# PIC32MX130F064B device description
Architecture: MIPS; Family: PIC32MX; Series: PIC32MX
Registers are 32-bit, read-write, no defined reset value unless marked. A register's access mark holds for its fields unless they carry their own. Offsets are from the block's base; [hi:lo] are bit positions; 'fields as' and 'values as' point back to an identical list.

## NVM
Instances: NVM 0x1f80f400 in periph1
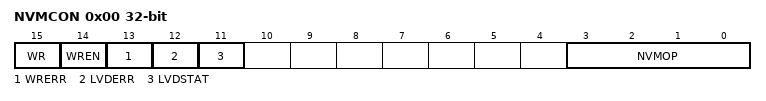
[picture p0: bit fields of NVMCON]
0x00 NVMCON — Programming Control Register
  [15] WR — Write Control bit
    1=Initiate a Flash operation. Hardware clears this bit when the operation completes; 0=Flash operation complete or inactive
  [14] WREN — Write Enable bit
    1=Enable writes to WR bit and enables LVD circuit; 0=Disable writes to WR bit and disables LVD circuit
  [13] WRERR — Write Error bit
    1=Program or erase sequence did not complete successfully; 0=Program or erase sequence completed normally
  [12] LVDERR — Low-Voltage Detect Error bit (LVD circuit must be enabled)
    1=Low-voltage detected (possible data corruption if WRERR is set); 0=Voltage level is acceptable for programming
  [11] LVDSTAT — Low-Voltage Detect Status bit (LVD circuit must be enabled)
    1=Low-voltage event active; 0=Low-voltage event NOT active
  [3:0] NVMOP — NVM Operation bits
    6=No operation; 5=Program Flash (PFM) erase operation: erases PFM if all pages are not write-protected; 4=Page erase operation: erases page selected by NVMADDR if it is not write-protected; 3=Row program operation: programs row selected by NVMADDR if it is not write-protected; 2=No operation; 1=Word program operation: programs word selected by NVMADDR if it is not write-protected; 0=No operation
0x10 NVMKEY wo — Programming Unlock Register
0x20 NVMADDR — Flash Address Register
0x30 NVMDATA
0x40 NVMSRCADDR — Source Data Address Register

## OCMP
Instances: OCMP 0x1f803000 in periph0
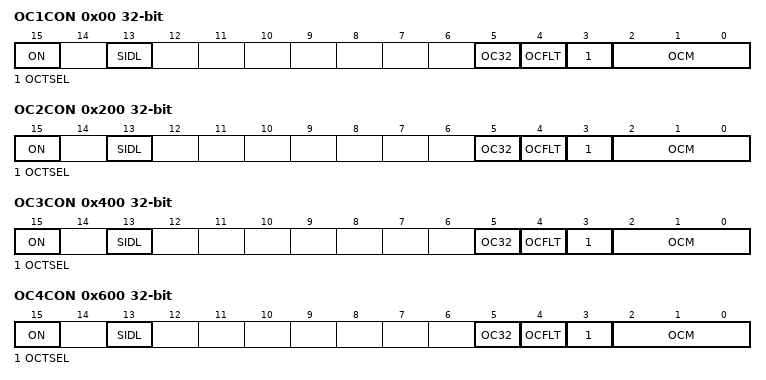
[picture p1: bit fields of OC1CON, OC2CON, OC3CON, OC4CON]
0x00 OC1CON — Output Compare 'x' Control Register
  [15] ON — Output Compare Peripheral On bit
    1=Output Compare peripheral is enabled; 0=Output Compare peripheral is disabled
  [13] SIDL — Stop in Idle Mode bit
    1=Discontinue operation when CPU enters Idle mode; 0=Continue operation in Idle mode
  [5] OC32 — 32-bit Compare Mode bit
    1=OCxR(31-0) and/or OCxRS(31-0) are used for comparisions to the 32-bit timer source; 0=OCxR(15-0) and OCxRS(15-0) are used for comparisons to the 16-bit timer source
  [4] OCFLT — PWM Fault Condition Status bit
    1=PWM Fault condition has occurred (cleared in HW only); 0=No PWM Fault condition has occurred
  [3] OCTSEL — Output Compare Timer Select bit
    1=Timer3 is the clock source for this Output Compare module; 0=Timer2 is the clock source for this Output Compare module
  [2:0] OCM — Output Compare Mode Select bits
    7=PWM mode on OCx; Fault pin enabled; 6=PWM mode on OCx; Fault pin disabled; 5=Initialize OCx pin low; generate continious output pulses on OCx pin; 4=Initialize OCx pin low: generate single output pulse on OCx pin; 3=Compare event toggles OCx pin; 2=Initialize OCx pin high; compare event forces OCx pin low; 1=Initialize OCx pin low; compare event forces OCx pin high; 0=Output compare peripheral is disabled but continues to draw current
0x10 OC1R
0x20 OC1RS
0x200 OC2CON — Output Compare 'x' Control Register
  fields as OC1CON
0x210 OC2R
0x220 OC2RS
0x400 OC3CON — Output Compare 'x' Control Register
  fields as OC1CON
0x410 OC3R
0x420 OC3RS
0x600 OC4CON — Output Compare 'x' Control Register
  fields as OC1CON
0x610 OC4R
0x620 OC4RS
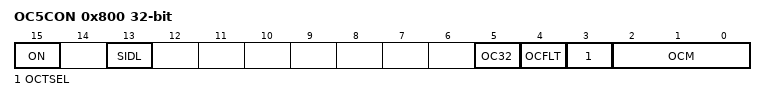
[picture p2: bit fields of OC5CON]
0x800 OC5CON — Output Compare 'x' Control Register
  fields as OC1CON
0x810 OC5R
0x820 OC5RS

## PORT
Instances: PORT 0x1f886000 in periph2
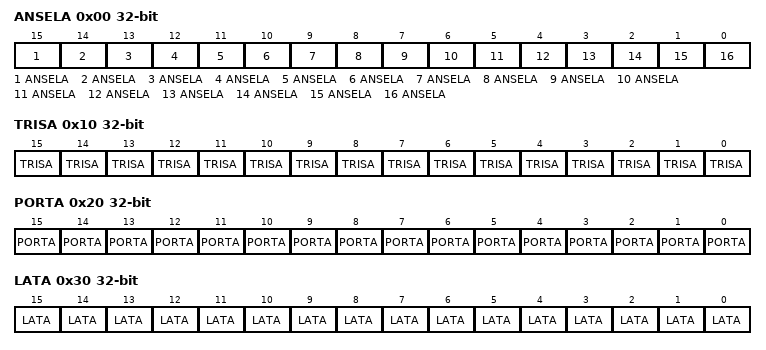
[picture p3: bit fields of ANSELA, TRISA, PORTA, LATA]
0x00 ANSELA
  [15] ANSELA, [14] ANSELA, [13] ANSELA, [12] ANSELA, [11] ANSELA, [10] ANSELA, [9] ANSELA, [8] ANSELA, [7] ANSELA, [6] ANSELA, [5] ANSELA, [4] ANSELA, [3] ANSELA, [2] ANSELA, [1] ANSELA, [0] ANSELA
0x10 TRISA
  [15] TRISA, [14] TRISA, [13] TRISA, [12] TRISA, [11] TRISA, [10] TRISA, [9] TRISA, [8] TRISA, [7] TRISA, [6] TRISA, [5] TRISA, [4] TRISA, [3] TRISA, [2] TRISA, [1] TRISA, [0] TRISA
0x20 PORTA
  [15] PORTA, [14] PORTA, [13] PORTA, [12] PORTA, [11] PORTA, [10] PORTA, [9] PORTA, [8] PORTA, [7] PORTA, [6] PORTA, [5] PORTA, [4] PORTA, [3] PORTA, [2] PORTA, [1] PORTA, [0] PORTA
0x30 LATA
  [15] LATA, [14] LATA, [13] LATA, [12] LATA, [11] LATA, [10] LATA, [9] LATA, [8] LATA, [7] LATA, [6] LATA, [5] LATA, [4] LATA, [3] LATA, [2] LATA, [1] LATA, [0] LATA
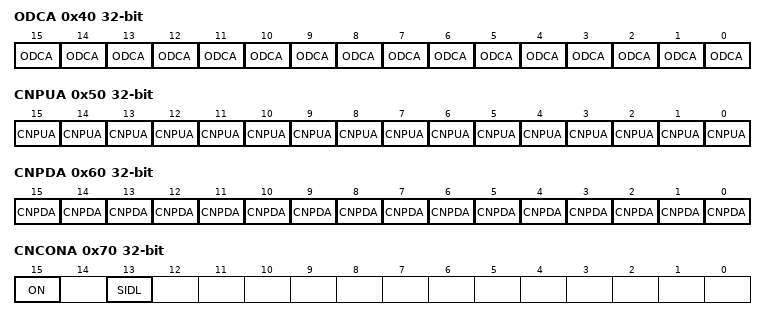
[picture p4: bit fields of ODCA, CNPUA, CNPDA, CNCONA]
0x40 ODCA
  [15] ODCA, [14] ODCA, [13] ODCA, [12] ODCA, [11] ODCA, [10] ODCA, [9] ODCA, [8] ODCA, [7] ODCA, [6] ODCA, [5] ODCA, [4] ODCA, [3] ODCA, [2] ODCA, [1] ODCA, [0] ODCA
0x50 CNPUA
  [15] CNPUA, [14] CNPUA, [13] CNPUA, [12] CNPUA, [11] CNPUA, [10] CNPUA, [9] CNPUA, [8] CNPUA, [7] CNPUA, [6] CNPUA, [5] CNPUA, [4] CNPUA, [3] CNPUA, [2] CNPUA, [1] CNPUA, [0] CNPUA
0x60 CNPDA
  [15] CNPDA, [14] CNPDA, [13] CNPDA, [12] CNPDA, [11] CNPDA, [10] CNPDA, [9] CNPDA, [8] CNPDA, [7] CNPDA, [6] CNPDA, [5] CNPDA, [4] CNPDA, [3] CNPDA, [2] CNPDA, [1] CNPDA, [0] CNPDA
0x70 CNCONA
  [15] ON, [13] SIDL
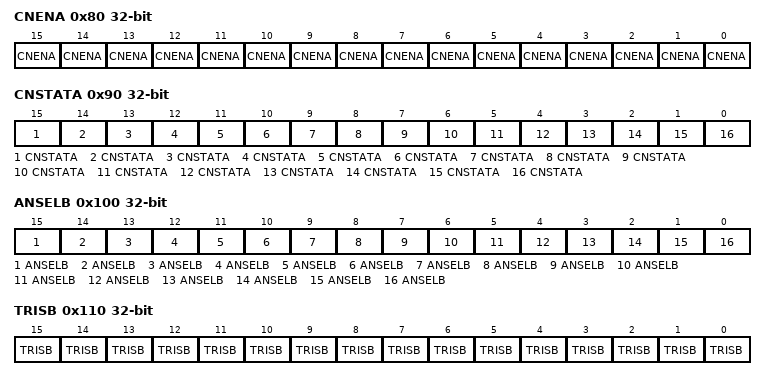
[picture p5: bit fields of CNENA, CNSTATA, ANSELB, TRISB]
0x80 CNENA
  [15] CNENA, [14] CNENA, [13] CNENA, [12] CNENA, [11] CNENA, [10] CNENA, [9] CNENA, [8] CNENA, [7] CNENA, [6] CNENA, [5] CNENA, [4] CNENA, [3] CNENA, [2] CNENA, [1] CNENA, [0] CNENA
0x90 CNSTATA
  [15] CNSTATA, [14] CNSTATA, [13] CNSTATA, [12] CNSTATA, [11] CNSTATA, [10] CNSTATA, [9] CNSTATA, [8] CNSTATA, [7] CNSTATA, [6] CNSTATA, [5] CNSTATA, [4] CNSTATA, [3] CNSTATA, [2] CNSTATA, [1] CNSTATA, [0] CNSTATA
0x100 ANSELB
  [15] ANSELB, [14] ANSELB, [13] ANSELB, [12] ANSELB, [11] ANSELB, [10] ANSELB, [9] ANSELB, [8] ANSELB, [7] ANSELB, [6] ANSELB, [5] ANSELB, [4] ANSELB, [3] ANSELB, [2] ANSELB, [1] ANSELB, [0] ANSELB
0x110 TRISB
  [15] TRISB, [14] TRISB, [13] TRISB, [12] TRISB, [11] TRISB, [10] TRISB, [9] TRISB, [8] TRISB, [7] TRISB, [6] TRISB, [5] TRISB, [4] TRISB, [3] TRISB, [2] TRISB, [1] TRISB, [0] TRISB
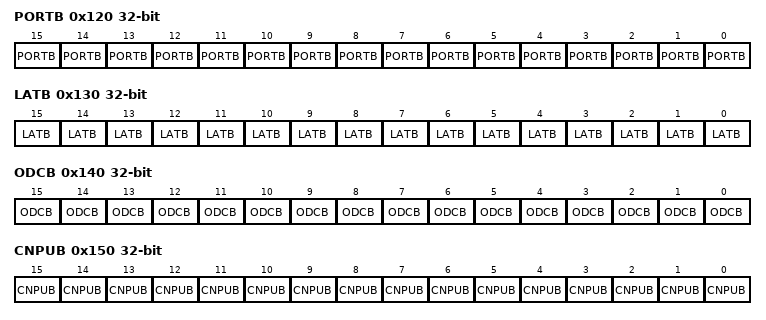
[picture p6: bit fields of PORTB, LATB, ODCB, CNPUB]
0x120 PORTB
  [15] PORTB, [14] PORTB, [13] PORTB, [12] PORTB, [11] PORTB, [10] PORTB, [9] PORTB, [8] PORTB, [7] PORTB, [6] PORTB, [5] PORTB, [4] PORTB, [3] PORTB, [2] PORTB, [1] PORTB, [0] PORTB
0x130 LATB
  [15] LATB, [14] LATB, [13] LATB, [12] LATB, [11] LATB, [10] LATB, [9] LATB, [8] LATB, [7] LATB, [6] LATB, [5] LATB, [4] LATB, [3] LATB, [2] LATB, [1] LATB, [0] LATB
0x140 ODCB
  [15] ODCB, [14] ODCB, [13] ODCB, [12] ODCB, [11] ODCB, [10] ODCB, [9] ODCB, [8] ODCB, [7] ODCB, [6] ODCB, [5] ODCB, [4] ODCB, [3] ODCB, [2] ODCB, [1] ODCB, [0] ODCB
0x150 CNPUB
  [15] CNPUB, [14] CNPUB, [13] CNPUB, [12] CNPUB, [11] CNPUB, [10] CNPUB, [9] CNPUB, [8] CNPUB, [7] CNPUB, [6] CNPUB, [5] CNPUB, [4] CNPUB, [3] CNPUB, [2] CNPUB, [1] CNPUB, [0] CNPUB
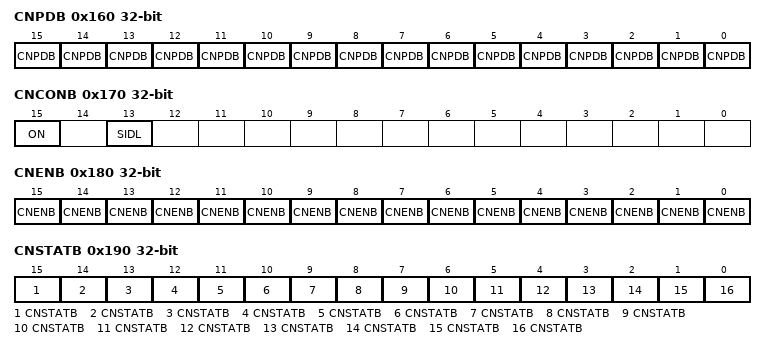
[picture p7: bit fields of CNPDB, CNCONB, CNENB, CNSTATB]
0x160 CNPDB
  [15] CNPDB, [14] CNPDB, [13] CNPDB, [12] CNPDB, [11] CNPDB, [10] CNPDB, [9] CNPDB, [8] CNPDB, [7] CNPDB, [6] CNPDB, [5] CNPDB, [4] CNPDB, [3] CNPDB, [2] CNPDB, [1] CNPDB, [0] CNPDB
0x170 CNCONB
  [15] ON, [13] SIDL
0x180 CNENB
  [15] CNENB, [14] CNENB, [13] CNENB, [12] CNENB, [11] CNENB, [10] CNENB, [9] CNENB, [8] CNENB, [7] CNENB, [6] CNENB, [5] CNENB, [4] CNENB, [3] CNENB, [2] CNENB, [1] CNENB, [0] CNENB
0x190 CNSTATB
  [15] CNSTATB, [14] CNSTATB, [13] CNSTATB, [12] CNSTATB, [11] CNSTATB, [10] CNSTATB, [9] CNSTATB, [8] CNSTATB, [7] CNSTATB, [6] CNSTATB, [5] CNSTATB, [4] CNSTATB, [3] CNSTATB, [2] CNSTATB, [1] CNSTATB, [0] CNSTATB

## Notices in the file
Copyright (c) 2019 Microchip Technology Inc.
SPDX-License-Identifier: Apache-2.0
Licensed under the Apache License, Version 2.0 (the "License");
you may not use this file except in compliance with the License.
You may obtain a copy of the License at
http://www.apache.org/licenses/LICENSE-2.0
Unless required by applicable law or agreed to in writing, software
distributed under the License is distributed on an "AS IS" BASIS,
WITHOUT WARRANTIES OR CONDITIONS OF ANY KIND, either express or implied.
See the License for the specific language governing permissions and
limitations under the License.
